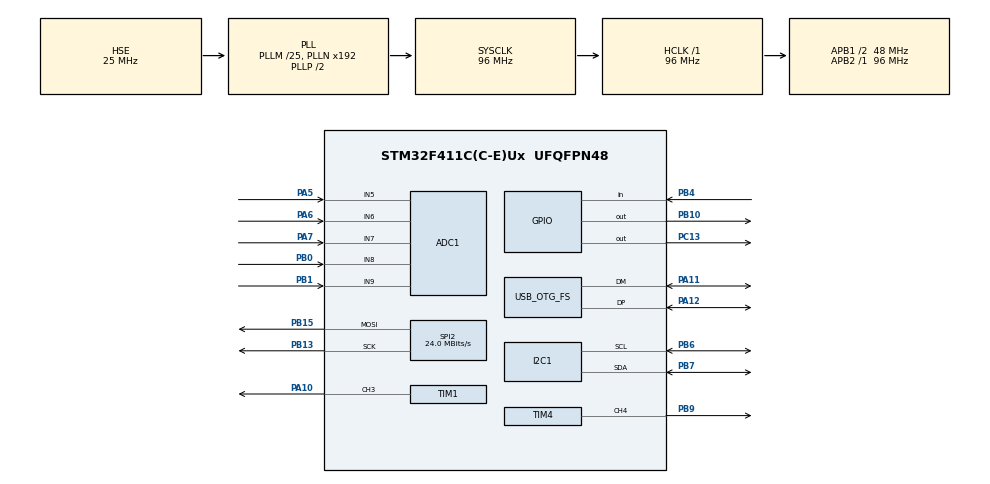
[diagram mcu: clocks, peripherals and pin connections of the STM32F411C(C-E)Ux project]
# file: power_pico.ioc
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ADC1.Channel-0\#ChannelRegularConversion=ADC_CHANNEL_5
ADC1.Channel-1\#ChannelRegularConversion=ADC_CHANNEL_6
ADC1.Channel-2\#ChannelRegularConversion=ADC_CHANNEL_7
ADC1.Channel-3\#ChannelRegularConversion=ADC_CHANNEL_8
ADC1.Channel-4\#ChannelRegularConversion=ADC_CHANNEL_9
ADC1.DMAContinuousRequests=ENABLE
ADC1.ExternalTrigConv=ADC_EXTERNALTRIGCONV_T2_TRGO
ADC1.NbrOfConversion=5
ADC1.NbrOfConversionFlag=1
ADC1.Rank-0\#ChannelRegularConversion=1
ADC1.Rank-1\#ChannelRegularConversion=2
ADC1.Rank-2\#ChannelRegularConversion=3
ADC1.Rank-3\#ChannelRegularConversion=4
ADC1.Rank-4\#ChannelRegularConversion=5
ADC1.SamplingTime-0\#ChannelRegularConversion=ADC_SAMPLETIME_28CYCLES
ADC1.SamplingTime-1\#ChannelRegularConversion=ADC_SAMPLETIME_28CYCLES
ADC1.SamplingTime-2\#ChannelRegularConversion=ADC_SAMPLETIME_28CYCLES
ADC1.SamplingTime-3\#ChannelRegularConversion=ADC_SAMPLETIME_28CYCLES
ADC1.SamplingTime-4\#ChannelRegularConversion=ADC_SAMPLETIME_28CYCLES
ADC1.master=1
Dma.ADC1.1.Direction=DMA_PERIPH_TO_MEMORY
Dma.ADC1.1.FIFOMode=DMA_FIFOMODE_DISABLE
Dma.ADC1.1.Instance=DMA2_Stream0
Dma.ADC1.1.MemDataAlignment=DMA_MDATAALIGN_HALFWORD
Dma.ADC1.1.MemInc=DMA_MINC_ENABLE
Dma.ADC1.1.Mode=DMA_CIRCULAR
Dma.ADC1.1.PeriphDataAlignment=DMA_PDATAALIGN_HALFWORD
Dma.ADC1.1.PeriphInc=DMA_PINC_DISABLE
Dma.ADC1.1.Priority=DMA_PRIORITY_LOW
Dma.Request0=SPI2_TX
Dma.Request1=ADC1
Dma.SPI2_TX.0.Direction=DMA_MEMORY_TO_PERIPH
Dma.SPI2_TX.0.FIFOMode=DMA_FIFOMODE_DISABLE
Dma.SPI2_TX.0.Instance=DMA1_Stream4
Dma.SPI2_TX.0.MemDataAlignment=DMA_MDATAALIGN_HALFWORD
Dma.SPI2_TX.0.MemInc=DMA_MINC_ENABLE
Dma.SPI2_TX.0.Mode=DMA_NORMAL
Dma.SPI2_TX.0.PeriphDataAlignment=DMA_PDATAALIGN_HALFWORD
Dma.SPI2_TX.0.PeriphInc=DMA_PINC_DISABLE
Dma.SPI2_TX.0.Priority=DMA_PRIORITY_LOW
FREERTOS.Tasks01=defaultTask,24,128,StartDefaultTask,Default,NULL,Dynamic,NULL,NULL
FREERTOS.configUSE_TICK_HOOK=1
Mcu.Family=STM32F4
Mcu.Name=STM32F411C(C-E)Ux
Mcu.Package=UFQFPN48
NVIC.DMA1_Stream4_IRQn=true\:5\:0\:true\:false\:true\:true\:false\:true\:true
NVIC.DMA2_Stream0_IRQn=true\:5\:0\:false\:false\:true\:true\:false\:true\:true
NVIC.OTG_FS_IRQn=true\:5\:0\:true\:false\:true\:true\:false\:true\:true
NVIC.PriorityGroup=NVIC_PRIORITYGROUP_4
NVIC.TIM1_TRG_COM_TIM11_IRQn=true\:15\:0\:false\:false\:true\:false\:false\:true\:true
NVIC.TimeBase=TIM1_TRG_COM_TIM11_IRQn
NVIC.TimeBaseIP=TIM11
PA10.Signal=S_TIM1_CH3
PA11.Mode=Device_Only
PA11.Signal=USB_OTG_FS_DM
PA12.Mode=Device_Only
PA12.Signal=USB_OTG_FS_DP
PA13.Mode=Serial_Wire
PA13.Signal=SYS_JTMS-SWDIO
PA14.Mode=Serial_Wire
PA14.Signal=SYS_JTCK-SWCLK
PA5.Signal=ADCx_IN5
PA6.Signal=ADCx_IN6
PA7.Signal=ADCx_IN7
PB0.Signal=ADCx_IN8
PB1.Signal=ADCx_IN9
PB10.Signal=GPIO_Output
PB13.Mode=TX_Only_Simplex_Unidirect_Master
PB13.Signal=SPI2_SCK
PB15.Mode=TX_Only_Simplex_Unidirect_Master
PB15.Signal=SPI2_MOSI
PB4.Signal=GPIO_Input
PB6.Mode=I2C
PB6.Signal=I2C1_SCL
PB7.Mode=I2C
PB7.Signal=I2C1_SDA
PB9.Signal=S_TIM4_CH4
PC13-ANTI_TAMP.Signal=GPIO_Output
PH0\ -\ OSC_IN.Mode=HSE-External-Oscillator
PH0\ -\ OSC_IN.Signal=RCC_OSC_IN
PH1\ -\ OSC_OUT.Mode=HSE-External-Oscillator
PH1\ -\ OSC_OUT.Signal=RCC_OSC_OUT
ProjectManager.HeapSize=0x200
ProjectManager.StackSize=0x400
ProjectManager.TargetToolchain=MDK-ARM V5.32
RCC.48MHZClocksFreq_Value=48000000
RCC.AHBFreq_Value=96000000
RCC.APB1CLKDivider=RCC_HCLK_DIV2
RCC.APB1Freq_Value=48000000
RCC.APB1TimFreq_Value=96000000
RCC.APB2Freq_Value=96000000
RCC.APB2TimFreq_Value=96000000
RCC.CortexFreq_Value=96000000
RCC.HCLKFreq_Value=96000000
RCC.HSE_VALUE=25000000
RCC.HSI_VALUE=16000000
RCC.LSE_VALUE=32768
RCC.PLLM=25
RCC.SYSCLKFreq_VALUE=96000000
RCC.SYSCLKSource=RCC_SYSCLKSOURCE_PLLCLK
RCC.VCOOutputFreq_Value=192000000
SH.ADCx_IN5.0=ADC1_IN5,IN5
SH.ADCx_IN6.0=ADC1_IN6,IN6
SH.ADCx_IN7.0=ADC1_IN7,IN7
SH.ADCx_IN8.0=ADC1_IN8,IN8
SH.ADCx_IN9.0=ADC1_IN9,IN9
SH.S_TIM1_CH3.0=TIM1_CH3,PWM Generation3 CH3
SH.S_TIM4_CH4.0=TIM4_CH4,PWM Generation4 CH4
SPI2.BaudRatePrescaler=SPI_BAUDRATEPRESCALER_2
SPI2.CLKPhase=SPI_PHASE_2EDGE
SPI2.CLKPolarity=SPI_POLARITY_HIGH
SPI2.CalculateBaudRate=24.0 MBits/s
SPI2.DataSize=SPI_DATASIZE_8BIT
SPI2.Direction=SPI_DIRECTION_2LINES
SPI2.FirstBit=SPI_FIRSTBIT_MSB
SPI2.Mode=SPI_MODE_MASTER
SPI2.VirtualType=VM_MASTER
TIM1.Channel-PWM\ Generation3\ CH3=TIM_CHANNEL_3
TIM1.Period=300
TIM1.Prescaler=95
TIM2.AutoReloadPreload=TIM_AUTORELOAD_PRELOAD_ENABLE
TIM2.Period=99
TIM2.Prescaler=95
TIM2.TIM_MasterOutputTrigger=TIM_TRGO_UPDATE
TIM4.Channel-PWM\ Generation4\ CH4=TIM_CHANNEL_4
TIM4.Period=500
TIM4.Prescaler=95
TIM4.Pulse-PWM\ Generation4\ CH4=250
TIM5.Channel-PWM\ Generation1\ No\ Output=TIM_CHANNEL_1
TIM5.Prescaler=95
USB_DEVICE.CLASS_NAME_FS=CDC
USB_DEVICE.VirtualMode=Cdc
USB_DEVICE.VirtualModeFS=Cdc_FS
USB_OTG_FS.VirtualMode=Device_Only
VP_FREERTOS_VS_CMSIS_V2.Mode=CMSIS_V2
VP_SYS_VS_tim11.Mode=TIM11
VP_TIM2_VS_ClockSourceITR.Mode=TriggerSource_ITR0
VP_TIM5_VS_no_output1.Mode=PWM Generation1 No Output
VP_USB_DEVICE_VS_USB_DEVICE_CDC_FS.Mode=CDC_FS
board=custom

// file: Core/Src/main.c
/* USER CODE BEGIN Header */
/**
  ******************************************************************************
  * @file           : main.c
  * @brief          : Main program body
  ******************************************************************************
  * @attention
  *
  * Copyright (c) 2025 STMicroelectronics.
  * All rights reserved.
  *
  * This software is licensed under terms that can be found in the LICENSE file
  * in the root directory of this software component.
  * If no LICENSE file comes with this software, it is provided AS-IS.
  *
  ******************************************************************************
  */
/* USER CODE END Header */
#include "main.h"
#include "cmsis_os.h"
#include "adc.h"
#include "dma.h"
#include "i2c.h"
#include "spi.h"
#include "tim.h"
#include "usb_device.h"
#include "gpio.h"

void SystemClock_Config(void);
void MX_FREERTOS_Init(void);

int main(void)
{

  /* USER CODE BEGIN 1 */
  //this must set same as keil setting
  SCB->VTOR = FLASH_BASE + 0x00000000U;
  /* USER CODE END 1 */

  /* MCU Configuration--------------------------------------------------------*/

  /* Reset of all peripherals, Initializes the Flash interface and the Systick. */
  HAL_Init();

  /* Configure the system clock */
  SystemClock_Config();

  /* USER CODE BEGIN SysInit */
  __enable_irq();
  /* USER CODE END SysInit */

  /* Initialize all configured peripherals */
  MX_GPIO_Init();
  MX_DMA_Init();
  MX_ADC1_Init();
  MX_TIM1_Init();
  MX_TIM4_Init();
  MX_SPI2_Init();
  MX_I2C1_Init();
  MX_TIM2_Init();
  MX_TIM5_Init();

  /* Init scheduler */
  osKernelInitialize();

  /* Call init function for freertos objects (in cmsis_os2.c) */
  MX_FREERTOS_Init();

  /* Start scheduler */
  osKernelStart();

  /* We should never get here as control is now taken by the scheduler */

  /* Infinite loop */
  while (1)
  {

  }
}

void SystemClock_Config(void)
{
  RCC_OscInitTypeDef RCC_OscInitStruct = {0};
  RCC_ClkInitTypeDef RCC_ClkInitStruct = {0};

  /** Configure the main internal regulator output voltage
  */
  __HAL_RCC_PWR_CLK_ENABLE();
  __HAL_PWR_VOLTAGESCALING_CONFIG(PWR_REGULATOR_VOLTAGE_SCALE1);

  /** Initializes the RCC Oscillators according to the specified parameters
  * in the RCC_OscInitTypeDef structure.
  */
  RCC_OscInitStruct.OscillatorType = RCC_OSCILLATORTYPE_HSE;
  RCC_OscInitStruct.HSEState = RCC_HSE_ON;
  RCC_OscInitStruct.PLL.PLLState = RCC_PLL_ON;
  RCC_OscInitStruct.PLL.PLLSource = RCC_PLLSOURCE_HSE;
  RCC_OscInitStruct.PLL.PLLM = 25;
  RCC_OscInitStruct.PLL.PLLN = 192;
  RCC_OscInitStruct.PLL.PLLP = RCC_PLLP_DIV2;
  RCC_OscInitStruct.PLL.PLLQ = 4;
  if (HAL_RCC_OscConfig(&RCC_OscInitStruct) != HAL_OK)
  {
    Error_Handler();
  }

  /** Initializes the CPU, AHB and APB buses clocks
  */
  RCC_ClkInitStruct.ClockType = RCC_CLOCKTYPE_HCLK|RCC_CLOCKTYPE_SYSCLK
                              |RCC_CLOCKTYPE_PCLK1|RCC_CLOCKTYPE_PCLK2;
  RCC_ClkInitStruct.SYSCLKSource = RCC_SYSCLKSOURCE_PLLCLK;
  RCC_ClkInitStruct.AHBCLKDivider = RCC_SYSCLK_DIV1;
  RCC_ClkInitStruct.APB1CLKDivider = RCC_HCLK_DIV2;
  RCC_ClkInitStruct.APB2CLKDivider = RCC_HCLK_DIV1;

  if (HAL_RCC_ClockConfig(&RCC_ClkInitStruct, FLASH_LATENCY_3) != HAL_OK)
  {
    Error_Handler();
  }
}

void HAL_TIM_PeriodElapsedCallback(TIM_HandleTypeDef *htim)
{
  if (htim->Instance == TIM11)
  {
    HAL_IncTick();
  }
}

void Error_Handler(void)
{
  __disable_irq();
  while (1)
  {
  }
}

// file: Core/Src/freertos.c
/* USER CODE BEGIN Header */
/**
  ******************************************************************************
  * File Name          : freertos.c
  * Description        : Code for freertos applications
  ******************************************************************************
  * @attention
  *
  * Copyright (c) 2025 STMicroelectronics.
  * All rights reserved.
  *
  * This software is licensed under terms that can be found in the LICENSE file
  * in the root directory of this software component.
  * If no LICENSE file comes with this software, it is provided AS-IS.
  *
  ******************************************************************************
  */
/* USER CODE END Header */

#include "FreeRTOS.h"
#include "task.h"
#include "main.h"
#include "cmsis_os.h"

/* USER CODE BEGIN Includes */
#include "user_TasksInit.h"
/* USER CODE END Includes */

/* Definitions for defaultTask */
osThreadId_t defaultTaskHandle;
const osThreadAttr_t defaultTask_attributes = {
  .name = "defaultTask",
  .stack_size = 128 * 4,
  .priority = (osPriority_t) osPriorityNormal,
};

void StartDefaultTask(void *argument);

extern void MX_USB_DEVICE_Init(void);
void MX_FREERTOS_Init(void); /* (MISRA C 2004 rule 8.1) */

/* Hook prototypes */
void vApplicationTickHook(void);

/* USER CODE BEGIN 3 */
void vApplicationTickHook( void )
{
   /* This function will be called by each tick interrupt if
   configUSE_TICK_HOOK is set to 1 in FreeRTOSConfig.h. User code can be
   added here, but the tick hook is called from an interrupt context, so
   code must not attempt to block, and only the interrupt safe FreeRTOS API
   functions can be used (those that end in FromISR()). */
  TaskTickHook();
}
/* USER CODE END 3 */

void MX_FREERTOS_Init(void) {
  /* USER CODE BEGIN Init */
  User_Tasks_Init();
  /* USER CODE END Init */

  /* Create the thread(s) */
  /* creation of defaultTask */
  defaultTaskHandle = osThreadNew(StartDefaultTask, NULL, &defaultTask_attributes);

}

void StartDefaultTask(void *argument)
{
  /* init code for USB_DEVICE */
  MX_USB_DEVICE_Init();
  /* USER CODE BEGIN StartDefaultTask */
  /* Infinite loop */
  for(;;)
  {
		HAL_GPIO_TogglePin(GPIOC, GPIO_PIN_13);
    osDelay(500);
  }
  /* USER CODE END StartDefaultTask */
}
